# AT90PWM161 device description
Architecture: AVR8; Family: megaAVR
Programming and debug interfaces: ISP, HVPP, debugWIRE
Registers are 8-bit, access not given, no defined reset value unless marked. A register's access mark holds for its fields unless they carry their own. Offsets are from the block's base; lines under a group give offsets from that group; [hi:lo] are bit positions; {n}, {i} and the like mark numbered series; 'fields as' and 'values as' point back to an identical list; <NAME> marks a mode.

## Ordering variants
standard: 2.7 to 5.5 V

## Memory
prog space: start 0x0000 size 0x4000, little endian
  0x0000 FLASH size 0x4000 flash, rw, executable, page 0x80
  0x3f00 BOOT_SECTION_1 size 0x0100 flash, rw, executable, page 0x80
  0x3e00 BOOT_SECTION_2 size 0x0200 flash, rw, executable, page 0x80
  0x3c00 BOOT_SECTION_3 size 0x0400 flash, rw, executable, page 0x80
  0x3800 BOOT_SECTION_4 size 0x0800 flash, rw, executable, page 0x80
signatures space: start 0 size 3, little endian
  0 SIGNATURES size 3 signatures, ro
fuses space: start 0 size 0x0003, little endian
  0 FUSES size 0x0003 fuses, rw
lockbits space: start 0 size 0x0001, little endian
  0 LOCKBITS size 0x0001 lockbits, rw
data space: start 0x0000 size 0x0500, little endian
  0x0000 REGISTERS size 0x0020 regs
  0x0020 MAPPED_IO size 0x00e0 io
  0x0100 IRAM size 0x0400 ram
eeprom space: start 0x0000 size 0x0200, little endian
  0x0000 EEPROM size 0x0200 eeprom, rw, page 0x04
io space: start 0x00 size 0x40, little endian
osccal space: start 0 size 2, little endian
  0 OSCCAL size 2 osccal, ro

## Peripheral instances (address, pins/pin function, parameters)
PORTB at 0x00 — I/O Port
PORTD at 0x00 — I/O Port
PORTE at 0x00 — I/O Port
DAC at 0x00 — Digital-to-Analog Converter
SPI at 0x00 — Serial Peripheral Interface
WDT at 0x00 — Watchdog Timer
EXINT at 0x00 — External Interrupts
ADC at 0x00 — Analog-to-Digital Converter
AC at 0x00 — Analog Comparator
CPU at 0x00 — CPU Registers
EEPROM at 0x00
PSC0 at 0x00 — Power Stage Controller
PSC2 at 0x00 — Power Stage Controller
TC1 at 0x00 — Timer/Counter, 16-bit
BOOT_LOAD at 0x00 — Bootloader
FUSE at 0 in fuses — Fuses
LOCKBIT at 0 in lockbits — Lockbits

## Interrupts
0 RESET — External Pin, Power-on Reset, Brown-out Reset, Watchdog Reset and JTAG AVR Reset
1 PSC2_CAPT — PSC2 Capture Event
2 PSC2_EC — PSC2 End Cycle
3 PSC2_EEC — PSC2 End Of Enhanced Cycle
4 PSC0_CAPT — PSC0 Capture Event
5 PSC0_EC — PSC0 End Cycle
6 PSC0_EEC — PSC0 End Of Enhanced Cycle
7 ANALOG_COMP_1 — Analog Comparator 1
8 ANALOG_COMP_2 — Analog Comparator 2
9 ANALOG_COMP_3 — Analog Comparator 3
10 INT0 — External Interrupt Request 0
11 TIMER1_CAPT — Timer/Counter1 Capture Event
12 TIMER1_OVF — Timer/Counter1 Overflow
13 ADC — ADC Conversion Complete
14 INT1 — External Interrupt Request 1
15 SPI_STC — SPI Serial Transfer Complet
16 INT2 — External Interrupt Request 2
17 WDT — Watchdog Timeout Interrupt
18 EE_READY — EEPROM Ready
19 SPM_READY — Store Program Memory Read

## Properties
SIGNATURES: JTAGID=0x948B, SIGNATURE0=0x1e, SIGNATURE1=0x94, SIGNATURE2=0x8B
OCD: OCD_REVISION=1, OCD_DATAREG=0x31, PROGBASE=0x0000

## LOCKBIT — Lockbits
Instances: LOCKBIT 0 in lockbits
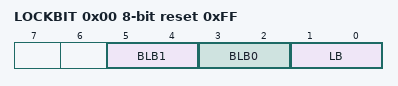
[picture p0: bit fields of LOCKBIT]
0x00 LOCKBIT reset 0xFF
  [5:4] BLB1 — Boot Loader Protection Mode
    0=LPM_SPM_DISABLE (LPM and SPM prohibited in Boot Section); 1=LPM_DISABLE (LPM prohibited in Boot Section); 2=SPM_DISABLE (SPM prohibited in Boot Section); 3=NO_LOCK (No lock on SPM and LPM in Boot Section)
  [3:2] BLB0 — Boot Loader Protection Mode
    0=LPM_SPM_DISABLE (LPM and SPM prohibited in Application Section); 1=LPM_DISABLE (LPM prohibited in Application Section); 2=SPM_DISABLE (SPM prohibited in Application Section); 3=NO_LOCK (No lock on SPM and LPM in Application Section)
  [1:0] LB — Memory Lock
    0=PROG_VER_DISABLED (Further programming and verification disabled); 2=PROG_DISABLED (Further programming disabled); 3=NO_LOCK (No memory lock features enabled)

## PORTB — I/O Port
Instances: PORTB 0x00
0x23 PINB — Port B Input Pins
0x24 DDRB — Port B Data Direction Register
0x25 PORTB — Port B Data Register
